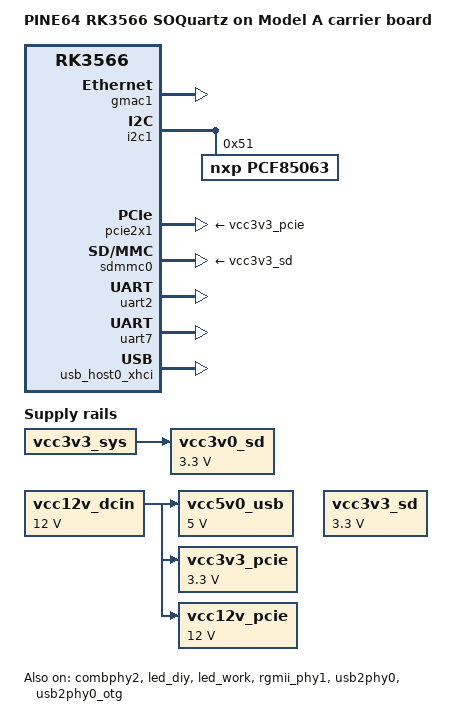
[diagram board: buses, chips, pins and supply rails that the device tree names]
/dts-v1/;
#include "rk3566-soquartz.dtsi"
/ {
	model = "PINE64 RK3566 SOQuartz on Model A carrier board";
	compatible = "pine64,soquartz-model-a", "pine64,soquartz", "rockchip,rk3566";
	vcc12v_dcin: vcc12v-dcin-regulator {
		compatible = "regulator-fixed";
		regulator-name = "vcc12v_dcin";
		regulator-always-on;
		regulator-boot-on;
		regulator-min-microvolt = <12000000>;
		regulator-max-microvolt = <12000000>;
	};
	vcc5v0_usb: vcc5v0-usb-regulator {
		compatible = "regulator-fixed";
		regulator-name = "vcc5v0_usb";
		regulator-always-on;
		regulator-boot-on;
		regulator-min-microvolt = <5000000>;
		regulator-max-microvolt = <5000000>;
		vin-supply = <&vcc12v_dcin>;
	};
	vcc3v0_sd: vcc3v0-sd-regulator {
		compatible = "regulator-fixed";
		regulator-name = "vcc3v0_sd";
		regulator-always-on;
		regulator-boot-on;
		regulator-min-microvolt = <3300000>;
		regulator-max-microvolt = <3300000>;
		vin-supply = <&vcc3v3_sys>;
	};
	vcc3v3_pcie: vcc3v3-pcie-regulator {
		compatible = "regulator-fixed";
		regulator-name = "vcc3v3_pcie";
		regulator-always-on;
		regulator-boot-on;
		regulator-min-microvolt = <3300000>;
		regulator-max-microvolt = <3300000>;
		vin-supply = <&vcc12v_dcin>;
	};
	vcc12v_pcie: vcc12v-pcie-regulator {
		compatible = "regulator-fixed";
		regulator-name = "vcc12v_pcie";
		regulator-always-on;
		regulator-boot-on;
		regulator-min-microvolt = <12000000>;
		regulator-max-microvolt = <12000000>;
		vin-supply = <&vcc12v_dcin>;
	};
};
&combphy2 {
	phy-supply = <&vcc3v3_sys>;
	status = "okay";
};
&gmac1 {
	status = "okay";
};
&i2c1 {
	status = "okay";
	pcf85063: rtc@51 {
		compatible = "nxp,pcf85063";
		reg = <0x51>;
	};
};
&i2c2 {
	status = "disabled";
};
&i2c3 {
	status = "disabled";
};
&i2c4 {
	status = "disabled";
};
&i2s1_8ch {
	status = "disabled";
};
&led_diy {
	status = "okay";
};
&led_work {
	status = "okay";
};
&pcie2x1 {
	vpcie3v3-supply = <&vcc3v3_pcie>;
	status = "okay";
};
&rgmii_phy1 {
	status = "okay";
};
&rgmii_phy1 {
	status = "okay";
};
&saradc {
	status = "disabled";
};
&sdmmc0 {
	vmmc-supply = <&vcc3v3_sd>;
	status = "okay";
};
&spi3 {
	status = "disabled";
};
&uart2 {
	status = "okay";
};
&uart7 {
	status = "okay";
};
&usb2phy0 {
	status = "okay";
};
&usb2phy0_otg {
	phy-supply = <&vcc5v0_usb>;
	status = "okay";
};
&usb_host0_xhci {
	status = "okay";
};
&vbus {
	vin-supply = <&vcc5v0_usb>;
};
&vcc3v3_sd {
	regulator-always-on;
	regulator-boot-on;
	regulator-min-microvolt = <3300000>;
	regulator-max-microvolt = <3300000>;
	status = "okay";
};
